# ESP32C5_RADIO register map
Vendor: Espressif; Series: ESP32-C5; File version: 0.1
Registers are 32-bit, read-write, no defined reset value unless marked. A register's access mark holds for its fields unless they carry their own. Offsets are from the block's base; [hi:lo] are bit positions; {n}, {i} and the like mark numbered series.

## MODEM_IEEE802154_OBSERVED — Sparse source-qualified word views in the existing owned MMIO aperture; individual meanings and side effects remain unknown.
Base 0x600A3000
0x98 WORD_0098_OPAQUE — Opaque: meaning not established. Aligned 32-bit bus view explicitly addressed by the cited vendor source. No reset or hardware write effect is established.
  [7:0] BITS_0_7_OPAQUE — Opaque: meaning not established. Observed source use; the individual hardware meaning is unknown.

## MODEM_ETM — ESP32-C5 modem event-task matrix at MODEM_BASE + 0x8800. The public IEEE 802.15.4 driver names the channel-enable, set and clear words and the per-channel event/task pair at an eight-byte stride from 0x18, and programs channels zero and one. Other channels and identifiers remain absent and no reset values are claimed.
Base 0x600A8800
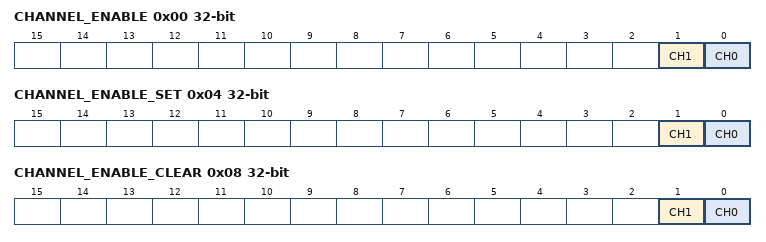
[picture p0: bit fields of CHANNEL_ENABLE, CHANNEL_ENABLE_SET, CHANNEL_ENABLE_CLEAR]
0x00 CHANNEL_ENABLE ro — Project-assigned name. Channel-enable status word. The IEEE 802.15.4 driver reads it to decide whether a channel must be disabled.
  [1] CH1 — Project-assigned name. Enabled state of channel 1.
  [0] CH0 — Project-assigned name. Enabled state of channel 0.
0x04 CHANNEL_ENABLE_SET — Project-assigned name. Channel-enable set word. The IEEE 802.15.4 driver reads it and writes it back with the selected channel bit added; the effect of writing other bits is not reviewed.
  [1] CH1 — Project-assigned name. Enable request of channel 1.
  [0] CH0 — Project-assigned name. Enable request of channel 0.
0x08 CHANNEL_ENABLE_CLEAR — Project-assigned name. Channel-enable clear word. The IEEE 802.15.4 driver reads it and writes it back with the selected channel bit added, only when that channel is enabled.
  [1] CH1 — Project-assigned name. Disable request of channel 1.
  [0] CH0 — Project-assigned name. Disable request of channel 0.
{0x18+8i} CH{i}_EVENT (i=0..1) — Project-assigned name. Complete event identifier monitored by the selected channel.
  [31:0] ID — Project-assigned name. Event identifier written as a complete word.
    58=IEEE802154_TIMER1_OVERFLOW; 59=IEEE802154_TIMER0_OVERFLOW
{0x1C+8i} CH{i}_TASK (i=0..1) — Project-assigned name. Complete task identifier triggered when the selected channel's event occurs.
  [31:0] ID — Project-assigned name. Task identifier written as a complete word.
    65=IEEE802154_ED_TRIG_TX; 66=IEEE802154_RX_START; 69=IEEE802154_TX_START

## MODEM_SYSCON_RADIO — ESP32-C5 MODEM_SYSCON clock gates and resets at MODEM_BASE + 0x9C00 driven by the vendor modem clock devices of the IEEE 802.15.4 module (802154_MAC, BT_I154_COMMON_BB, ETM, BT_APB) and its MAC reset. Other fields remain absent and are preserved by every field transaction.
Base 0x600A9C00
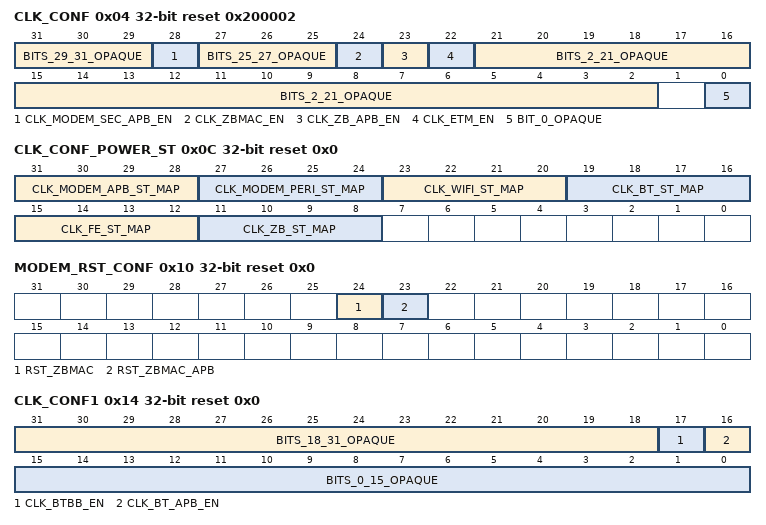
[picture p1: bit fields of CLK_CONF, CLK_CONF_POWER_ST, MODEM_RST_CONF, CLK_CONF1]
0x04 CLK_CONF reset 0x200002 — Modem clock selectors and protocol clock gates.
  [31:29] BITS_29_31_OPAQUE — Opaque: meaning not established. Observed source use; the individual hardware meaning is unknown.
  [28] CLK_MODEM_SEC_APB_EN — Enable the modem-security APB clock.
  [27:25] BITS_25_27_OPAQUE — Opaque: meaning not established. Observed source use; the individual hardware meaning is unknown.
  [24] CLK_ZBMAC_EN — Enable the IEEE 802.15.4 MAC clock.
  [23] CLK_ZB_APB_EN — Enable the IEEE 802.15.4 APB clock.
  [22] CLK_ETM_EN — Enable the modem ETM clock.
  [21:2] BITS_2_21_OPAQUE — Opaque: meaning not established. Observed source use; the individual hardware meaning is unknown.
  [0] BIT_0_OPAQUE — Opaque: meaning not established. Observed source use; the individual hardware meaning is unknown.
0x0C CLK_CONF_POWER_ST reset 0x0 — Modem clock power-state mapping. Only the documented fields at bits 31:8 have a known zero reset; bits 7:0 remain unknown. SOURCE: ESP_IDF_4D59230D_C5_MODEM_SYSCON_POWER_ST_RESET.
  [31:28] CLK_MODEM_APB_ST_MAP — Power states that enable the modem APB clock domain.
  [27:24] CLK_MODEM_PERI_ST_MAP — Power states that enable the modem peripheral clock domain.
  [23:20] CLK_WIFI_ST_MAP — Power states that enable the Wi-Fi clock domain.
  [19:16] CLK_BT_ST_MAP — Power states that enable the Bluetooth clock domain.
  [15:12] CLK_FE_ST_MAP — Power states that enable the front-end clock domain.
  [11:8] CLK_ZB_ST_MAP — Power states that enable the IEEE 802.15.4 clock domain.
0x10 MODEM_RST_CONF reset 0x0 — Modem protocol reset lines.
  [24] RST_ZBMAC — Hold the IEEE 802.15.4 MAC in reset.
  [23] RST_ZBMAC_APB — Hold the IEEE 802.15.4 APB interface in reset.
0x14 CLK_CONF1 reset 0x0 — Wi-Fi, front-end and Bluetooth clock gates.
  [31:18] BITS_18_31_OPAQUE — Opaque: meaning not established. Observed source use; the individual hardware meaning is unknown.
  [17] CLK_BTBB_EN — Enable the baseband clock shared by Bluetooth LE and IEEE 802.15.4.
  [16] CLK_BT_APB_EN — Enable the Bluetooth APB clock.
  [15:0] BITS_0_15_OPAQUE — Opaque: meaning not established. Observed source use; the individual hardware meaning is unknown.
